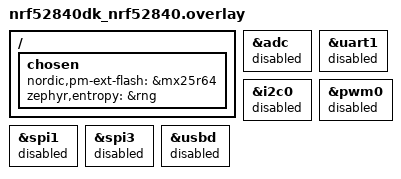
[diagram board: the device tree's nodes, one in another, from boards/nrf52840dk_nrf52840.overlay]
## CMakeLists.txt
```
#
# Copyright (c) 2021 Nordic Semiconductor ASA
#
# SPDX-License-Identifier: LicenseRef-Nordic-5-Clause
#

cmake_minimum_required(VERSION 3.20.0)

find_package(Zephyr HINTS $ENV{ZEPHYR_BASE})

project(matter-template)

# Enable GNU STD support and initialize the Matter Data Model.
include(${ZEPHYR_CONNECTEDHOMEIP_MODULE_DIR}/config/nrfconnect/app/enable-gnu-std.cmake)
include(${ZEPHYR_CONNECTEDHOMEIP_MODULE_DIR}/src/app/chip_data_model.cmake)

# NORDIC SDK APP START

# Include all source files that are located in the Matter common directory.
include(${ZEPHYR_NRF_MODULE_DIR}/samples/matter/common/cmake/source_common.cmake)

target_include_directories(app PRIVATE
    src
    ${CONFIG_NCS_SAMPLE_MATTER_ZAP_FILES_PATH}
)

target_sources(app PRIVATE
    src/app_task.cpp
    src/main.cpp
)

chip_configure_data_model(app
    INCLUDE_SERVER
    BYPASS_IDL
    GEN_DIR ${CONFIG_NCS_SAMPLE_MATTER_ZAP_FILES_PATH}/zap-generated
    ZAP_FILE ${CMAKE_CURRENT_SOURCE_DIR}/${CONFIG_NCS_SAMPLE_MATTER_ZAP_FILES_PATH}/template.zap
)
# NORDIC SDK APP END
```

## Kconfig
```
#
# Copyright (c) 2022 Nordic Semiconductor
#
# SPDX-License-Identifier: LicenseRef-Nordic-5-Clause
#
mainmenu "Matter nRF Connect Template Example Application"

# Sample configuration used for Thread networking
if NET_L2_OPENTHREAD

choice OPENTHREAD_NORDIC_LIBRARY_CONFIGURATION
	default OPENTHREAD_NORDIC_LIBRARY_MTD
endchoice

choice OPENTHREAD_DEVICE_TYPE
	default OPENTHREAD_MTD
endchoice

endif # NET_L2_OPENTHREAD

source "${ZEPHYR_CONNECTEDHOMEIP_MODULE_DIR}/config/nrfconnect/chip-module/Kconfig.features"
source "${ZEPHYR_CONNECTEDHOMEIP_MODULE_DIR}/config/nrfconnect/chip-module/Kconfig.defaults"
source "${ZEPHYR_NRF_MODULE_DIR}/samples/matter/common/src/Kconfig"
source "Kconfig.zephyr"
```

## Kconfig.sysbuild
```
#
# Copyright (c) 2023 Nordic Semiconductor ASA
#
# SPDX-License-Identifier: LicenseRef-Nordic-5-Clause
#

config WIFI_NRF70
	default y if BOARD_NRF7002DK

#### Radio core selection
config NRF_DEFAULT_IPC_RADIO
	default y

# Enable IEEE802.15.4 serialization to network core
# This config automatically pulls in the `overlay-802154.conf` in the ipc_radio image
config NETCORE_IPC_RADIO_IEEE802154
	default y if (SOC_SERIES_NRF53X || SOC_SERIES_NRF54HX) && !WIFI_NRF70

# Enable Bluetooth serialization to network core
# This config automatically pulls in the `overlay-bt_hci_ipc.conf` in the ipc_radio image
config NETCORE_IPC_RADIO_BT_HCI_IPC
	default y if (SOC_SERIES_NRF53X || SOC_SERIES_NRF54HX)

#### Bootloader
choice BOOTLOADER
	default BOOTLOADER_MCUBOOT if !BOARD_NRF21540DK && !SOC_SERIES_NRF54HX
endchoice

if BOOTLOADER_MCUBOOT

#### DFU multi-image support
config DFU_MULTI_IMAGE_PACKAGE_BUILD
	default y

config DFU_MULTI_IMAGE_PACKAGE_APP
	default y

config PM_EXTERNAL_FLASH_MCUBOOT_SECONDARY
	default y

#### DFU network core configuration
if SOC_SERIES_NRF53X

config MCUBOOT_UPDATEABLE_IMAGES
	default 2

choice MCUBOOT_MODE
	default MCUBOOT_MODE_OVERWRITE_ONLY
endchoice

choice BOOT_SIGNATURE_TYPE
	default BOOT_SIGNATURE_TYPE_RSA
endchoice

config SECURE_BOOT_NETCORE
	default y

config NETCORE_APP_UPDATE
	default y

config DFU_MULTI_IMAGE_PACKAGE_NET
	default y

endif # SOC_SERIES_NRF53X

if BOARD_NRF54L15DK

# Disable checking the external drivers for nRF54L15 DKs.
config PM_OVERRIDE_EXTERNAL_DRIVER_CHECK
	default y

# override the mcuboot pad size, because it is not set globally for NS build.
config PM_MCUBOOT_PAD
	default 0x800

endif # BOARD_NRF54L15DK

endif # BOOTLOADER_MCUBOOT

if SOC_SERIES_NRF54HX

config SUIT_ENVELOPE
	default y

config SUIT_BUILD_FLASH_COMPANION
	default y

config SUIT_MULTI_IMAGE_PACKAGE_BUILD
	default y if MATTER_OTA

endif # SOC_SERIES_NRF54HX

#### Enable generating factory data
config MATTER_FACTORY_DATA_GENERATE
	default y if !BOARD_NRF21540DK

source "${ZEPHYR_BASE}/share/sysbuild/Kconfig"
```

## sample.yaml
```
sample:
  description: Matter Template sample
  name: Matter Template
tests:
  sample.matter.template.debug:
    sysbuild: true
    build_only: true
    extra_args: CONFIG_NCS_SAMPLE_MATTER_OPERATIONAL_KEYS_MIGRATION_TO_ITS=y
    integration_platforms:
      - nrf52840dk/nrf52840
      - nrf5340dk/nrf5340/cpuapp
      - nrf7002dk/nrf5340/cpuapp
      - nrf54l15dk/nrf54l15/cpuapp
      - nrf54l15dk/nrf54l15/cpuapp/ns
      - nrf54l15dk/nrf54l10/cpuapp
    platform_allow: nrf52840dk/nrf52840 nrf5340dk/nrf5340/cpuapp nrf7002dk/nrf5340/cpuapp
      nrf54l15dk/nrf54l15/cpuapp nrf54l15dk/nrf54l15/cpuapp/ns nrf54l15dk/nrf54l10/cpuapp
    tags: sysbuild ci_samples_matter
  sample.matter.template.release:
    sysbuild: true
    build_only: true
    extra_args: FILE_SUFFIX=release
      CONFIG_NCS_SAMPLE_MATTER_OPERATIONAL_KEYS_MIGRATION_TO_ITS=y
    integration_platforms:
      - nrf52840dk/nrf52840
      - nrf5340dk/nrf5340/cpuapp
      - nrf7002dk/nrf5340/cpuapp
      - nrf54l15dk/nrf54l15/cpuapp
      - nrf54l15dk/nrf54l15/cpuapp/ns
      - nrf54l15dk/nrf54l10/cpuapp
    platform_allow: nrf52840dk/nrf52840 nrf5340dk/nrf5340/cpuapp nrf7002dk/nrf5340/cpuapp
      nrf54l15dk/nrf54l15/cpuapp nrf54l15dk/nrf54l15/cpuapp/ns nrf54l15dk/nrf54l10/cpuapp
    tags: sysbuild ci_samples_matter
  sample.matter.template.lto:
    sysbuild: true
    build_only: true
    extra_args: CONFIG_NCS_SAMPLE_MATTER_OPERATIONAL_KEYS_MIGRATION_TO_ITS=y
      CONFIG_LTO=y CONFIG_ISR_TABLES_LOCAL_DECLARATION=y
    integration_platforms:
      - nrf52840dk/nrf52840
      - nrf5340dk/nrf5340/cpuapp
      - nrf7002dk/nrf5340/cpuapp
      - nrf54l15dk/nrf54l15/cpuapp
      - nrf54l15dk/nrf54l10/cpuapp
    platform_allow: nrf52840dk/nrf52840 nrf5340dk/nrf5340/cpuapp nrf7002dk/nrf5340/cpuapp
      nrf54l15dk/nrf54l15/cpuapp nrf54l15dk/nrf54l10/cpuapp
    tags: sysbuild ci_samples_matter
  sample.matter.template.smp_dfu:
    sysbuild: true
    build_only: true
    extra_args: CONFIG_CHIP_DFU_OVER_BT_SMP=y
      CONFIG_NCS_SAMPLE_MATTER_OPERATIONAL_KEYS_MIGRATION_TO_ITS=y
    integration_platforms:
      - nrf52840dk/nrf52840
      - nrf5340dk/nrf5340/cpuapp
      - nrf7002dk/nrf5340/cpuapp
      - nrf54l15dk/nrf54l15/cpuapp
      - nrf54l15dk/nrf54l15/cpuapp/ns
      - nrf54l15dk/nrf54l10/cpuapp
    platform_allow: nrf52840dk/nrf52840 nrf5340dk/nrf5340/cpuapp nrf7002dk/nrf5340/cpuapp
      nrf54l15dk/nrf54l15/cpuapp nrf54l15dk/nrf54l15/cpuapp/ns nrf54l15dk/nrf54l10/cpuapp
    tags: sysbuild ci_samples_matter
  sample.matter.template.smp_dfu.nrf54h20:
    sysbuild: true
    build_only: true
    extra_args: CONFIG_CHIP_DFU_OVER_BT_SMP=y
    integration_platforms:
      - nrf54h20dk/nrf54h20/cpuapp
    platform_allow: nrf54h20dk/nrf54h20/cpuapp
    tags: sysbuild ci_samples_matter
  sample.matter.template.nrf54h20.nrf7002eb:
    sysbuild: true
    build_only: true
    extra_args:
      - SB_CONFIG_WIFI_NRF70=y
      - template_SHIELD=nrf7002eb_interposer_p1 nrf7002eb
      - CONFIG_CHIP_WIFI=y
      - CONFIG_CHIP_BOOTLOADER_NONE=y
      - CONFIG_CHIP_OTA_REQUESTOR=n
      - SB_CONFIG_MATTER_OTA=n
      - CONFIG_LTO=y
      - CONFIG_ISR_TABLES_LOCAL_DECLARATION=y
    integration_platforms:
      - nrf54h20dk/nrf54h20/cpuapp
    platform_allow: nrf54h20dk/nrf54h20/cpuapp
    tags: sysbuild ci_samples_matter
  sample.matter.template.release.internal.smp_dfu:
    sysbuild: true
    build_only: true
    extra_args: FILE_SUFFIX=internal CONFIG_CHIP_DFU_OVER_BT_SMP=y
      CONFIG_NCS_SAMPLE_MATTER_OPERATIONAL_KEYS_MIGRATION_TO_ITS=y
    integration_platforms:
      - nrf54l15dk/nrf54l15/cpuapp
    platform_allow: nrf54l15dk/nrf54l15/cpuapp
    tags: sysbuild ci_samples_matter
  sample.matter.template.cc3xx_backend:
    sysbuild: true
    build_only: true
    extra_args: CONFIG_PSA_CRYPTO_DRIVER_CC3XX=y
    integration_platforms:
      - nrf52840dk/nrf52840
      - nrf5340dk/nrf5340/cpuapp
    platform_allow: nrf52840dk/nrf52840 nrf5340dk/nrf5340/cpuapp
    tags: sysbuild ci_samples_matter
```

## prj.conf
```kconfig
#
# Copyright (c) 2021 Nordic Semiconductor ASA
#
# SPDX-License-Identifier: LicenseRef-Nordic-5-Clause
#

# This sample uses Kconfig.defaults to set options common for all
# samples. This file should contain only options specific for this sample
# or overrides of default values.

# Enable CHIP
CONFIG_CHIP=y
CONFIG_CHIP_PROJECT_CONFIG="src/chip_project_config.h"
# 32768 == 0x8000 (example Product ID added temporaly,
# but it must be changed with proper PID from the list:
# https://github.com/project-chip/connectedhomeip/blob/482e6fd03196a6de45465a90003947ef4b86e0b1/docs/examples/discussion/PID_allocation_for_example_apps.md)
CONFIG_CHIP_DEVICE_PRODUCT_ID=32768
CONFIG_STD_CPP17=y

# Enable Matter pairing automatically on application start.
CONFIG_CHIP_ENABLE_PAIRING_AUTOSTART=y

# Enable Matter extended announcement and increase duration to 1 hour.
CONFIG_CHIP_BLE_EXT_ADVERTISING=y
CONFIG_CHIP_BLE_ADVERTISING_DURATION=60

# Add support for LEDs and buttons on Nordic development kits
CONFIG_DK_LIBRARY=y

# Bluetooth Low Energy configuration
CONFIG_BT_DEVICE_NAME="MatterTemplate"

# Other settings
CONFIG_THREAD_NAME=y
CONFIG_MPU_STACK_GUARD=y
CONFIG_RESET_ON_FATAL_ERROR=n
CONFIG_CHIP_LIB_SHELL=y
CONFIG_NCS_SAMPLE_MATTER_TEST_SHELL=y

# Disable NFC commissioning
CONFIG_CHIP_NFC_COMMISSIONING=n

# Reduce application size
CONFIG_USE_SEGGER_RTT=n

# Enable Factory Data feature
CONFIG_CHIP_FACTORY_DATA=y
CONFIG_CHIP_FACTORY_DATA_BUILD=y
```

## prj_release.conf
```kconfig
#
# Copyright (c) 2021 Nordic Semiconductor ASA
#
# SPDX-License-Identifier: LicenseRef-Nordic-5-Clause
#

# This sample uses Kconfig.defaults to set options common for all
# samples. This file should contain only options specific for this sample
# or overrides of default values.

# Enable CHIP
CONFIG_CHIP=y
CONFIG_CHIP_PROJECT_CONFIG="src/chip_project_config.h"
# 32768 == 0x8000 (example Product ID added temporaly,
# but it must be changed with proper PID from the list:
# https://github.com/project-chip/connectedhomeip/blob/482e6fd03196a6de45465a90003947ef4b86e0b1/docs/examples/discussion/PID_allocation_for_example_apps.md)
CONFIG_CHIP_DEVICE_PRODUCT_ID=32768
CONFIG_STD_CPP17=y

# Enable Matter pairing automatically on application start.
CONFIG_CHIP_ENABLE_PAIRING_AUTOSTART=y

# Enable Matter extended announcement and increase duration to 1 hour.
CONFIG_CHIP_BLE_EXT_ADVERTISING=y
CONFIG_CHIP_BLE_ADVERTISING_DURATION=60

# Add support for LEDs and buttons on Nordic development kits
CONFIG_DK_LIBRARY=y

# Bluetooth Low Energy configuration
CONFIG_BT_DEVICE_NAME="MatterTemplate"

# Enable system reset on fatal error
CONFIG_RESET_ON_FATAL_ERROR=y

# Disable all debug features
CONFIG_USE_SEGGER_RTT=n
CONFIG_SHELL=n
CONFIG_OPENTHREAD_SHELL=n
CONFIG_CONSOLE=n
CONFIG_UART_CONSOLE=n
CONFIG_SERIAL=n
CONFIG_LOG=n
CONFIG_LOG_MODE_MINIMAL=n
CONFIG_ASSERT_VERBOSE=n
CONFIG_ASSERT_NO_FILE_INFO=y
CONFIG_PRINTK=n
CONFIG_PRINTK_SYNC=n
CONFIG_THREAD_NAME=n
CONFIG_BOOT_BANNER=n

# Disable NFC commissioning
CONFIG_CHIP_NFC_COMMISSIONING=n

# Enable Factory Data feature
CONFIG_CHIP_FACTORY_DATA=y
CONFIG_CHIP_FACTORY_DATA_BUILD=y

# Enable Watchdog
CONFIG_NCS_SAMPLE_MATTER_WATCHDOG=y
```

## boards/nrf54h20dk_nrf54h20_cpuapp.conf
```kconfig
#
# Copyright (c) 2024 Nordic Semiconductor ASA
#
# SPDX-License-Identifier: LicenseRef-Nordic-5-Clause
#

# Disable Oberon PSA crypto drivers
CONFIG_PSA_CRYPTO_DRIVER_OBERON=n

# Enable PSA crypto from SSF client
CONFIG_PSA_SSF_CRYPTO_CLIENT=y
CONFIG_SSF_PSA_CRYPTO_SERVICE_ENABLED=y

# Disable Data Cache
CONFIG_DCACHE=n

# Set the ZMS sector count to match the settings partition size that is 32 kB for this application.
CONFIG_SETTINGS_ZMS_SECTOR_COUNT=8
# Workaround required as Zephyr L2 implies usage of NVS backend for settings.
# It should be removed once the proper fix will be applied in Zephyr.
CONFIG_NVS=n

# Enable cache processing for application core.
# It will add the application firmware to the cache partition.
CONFIG_SUIT_DFU_CACHE_EXTRACT_IMAGE=y

# TODO: Enable factory data and DAC key migration once it is available
CONFIG_CHIP_FACTORY_DATA=n
CONFIG_CHIP_CRYPTO_PSA_MIGRATE_DAC_PRIV_KEY=n

# TODO: Workaround to be removed once Zephyr's CONFIG_FPROTECT is supported on nRF54H20.
CONFIG_CHIP_FACTORY_DATA_WRITE_PROTECT=n

# Disable GPD
CONFIG_SOC_NRF54H20_GPD=n
```

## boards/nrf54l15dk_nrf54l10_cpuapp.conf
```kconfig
#
# Copyright (c) 2024 Nordic Semiconductor ASA
#
# SPDX-License-Identifier: LicenseRef-Nordic-5-Clause
#

# Multirole is the only currently supported role by SoftDevice.
CONFIG_BT_LL_SOFTDEVICE_MULTIROLE=y

# nRF54L15 requires bigger stack sizes than nRF52/nRF53 families
CONFIG_CHIP_MALLOC_SYS_HEAP_SIZE=10240
CONFIG_MPSL_WORK_STACK_SIZE=2048

# Set the ZMS sector count to match the settings partition size that is 40 kB for this application.
CONFIG_SETTINGS_ZMS_SECTOR_COUNT=10

# Workaround required as Zephyr L2 implies usage of NVS backend for settings.
# It should be removed once the proper fix will be applied in Zephyr.
CONFIG_NVS=n

# Disabling of unused RAM blocks to reduce power consumption is not yet available for nRF54L10 SoC
CONFIG_RAM_POWER_DOWN_LIBRARY=n
```

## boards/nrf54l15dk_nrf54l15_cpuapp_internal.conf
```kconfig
#
# Copyright (c) 2024 Nordic Semiconductor ASA
#
# SPDX-License-Identifier: LicenseRef-Nordic-5-Clause
#

# Multirole is the only currently supported role by SoftDevice.
CONFIG_BT_LL_SOFTDEVICE_MULTIROLE=y

# nRF54L15 requires bigger stack sizes than nRF52/nRF53 families
CONFIG_CHIP_MALLOC_SYS_HEAP_SIZE=10240
CONFIG_MPSL_WORK_STACK_SIZE=2048

# Set the ZMS sector count to match the settings partition size that is 40 kB for this application.
CONFIG_SETTINGS_ZMS_SECTOR_COUNT=10
# Workaround required as Zephyr L2 implies usage of NVS backend for settings.
# It should be removed once the proper fix will be applied in Zephyr.
CONFIG_NVS=n

# Disable SPI
CONFIG_CHIP_SPI_NOR=n

# Enable Watchdog
CONFIG_NCS_SAMPLE_MATTER_WATCHDOG=y

# Enable LTO
CONFIG_LTO=y
CONFIG_ISR_TABLES_LOCAL_DECLARATION=y
```

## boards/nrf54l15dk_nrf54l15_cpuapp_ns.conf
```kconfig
#
# Copyright (c) 2024 Nordic Semiconductor ASA
#
# SPDX-License-Identifier: LicenseRef-Nordic-5-Clause
#

# Multirole is the only currently supported role by SoftDevice.
CONFIG_BT_LL_SOFTDEVICE_MULTIROLE=y

# TODO: Workaround to be removed once Zephyr's CONFIG_FPROTECT is supported on nRF54L_ns
CONFIG_CHIP_FACTORY_DATA_WRITE_PROTECT=n

# nRF54L15 requires bigger stack sizes than nRF52/nRF53 families
CONFIG_CHIP_MALLOC_SYS_HEAP_SIZE=10240
CONFIG_MPSL_WORK_STACK_SIZE=2048

# Set the ZMS sector count to match the settings partition size that is 40 kB for this application.
CONFIG_SETTINGS_ZMS_SECTOR_COUNT=10
# Workaround required as Zephyr L2 implies usage of NVS backend for settings.
# It should be removed once the proper fix will be applied in Zephyr.
CONFIG_NVS=n
```

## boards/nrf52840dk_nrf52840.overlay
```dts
/* Copyright (c) 2021 Nordic Semiconductor ASA
 *
 * SPDX-License-Identifier: LicenseRef-Nordic-5-Clause
 */

/ {
	chosen {
		nordic,pm-ext-flash = &mx25r64;
	};
};


/ {
	/*
	* In some default configurations within the nRF Connect SDK,
	* e.g. on nRF52840, the chosen zephyr,entropy node is &cryptocell.
	* This devicetree overlay ensures that default is overridden wherever it
	* is set, as this application uses the RNG node for entropy exclusively.
	*/
	chosen {
		zephyr,entropy = &rng;
	};
};

/* Disable unused peripherals to reduce power consumption */
&adc {
	status = "disabled";
};
&uart1 {
	status = "disabled";
};
&i2c0 {
	status = "disabled";
};
&pwm0 {
	status = "disabled";
};
&spi1 {
	status = "disabled";
};
&spi3 {
	status = "disabled";
};
&usbd {
	status = "disabled";
};
```

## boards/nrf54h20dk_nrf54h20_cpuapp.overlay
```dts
/*
 * Copyright (c) 2024 Nordic Semiconductor ASA
 *
 * SPDX-License-Identifier: LicenseRef-Nordic-5-Clause
 */

// Base path of the following includes points to the nrf/include directory.
#include <../samples/matter/common/dts/nrf54h20/nrf54h20_cpuapp_peripherals.dtsi>
#include <../samples/matter/common/dts/nrf54h20/nrf54h20_cpuapp_memory_map.dtsi>
#include <../samples/matter/common/dts/nrf54h20/nrf54h20_ram_allocation.dtsi>
```

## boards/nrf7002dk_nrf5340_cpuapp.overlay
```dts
/*
 * Copyright (c) 2021 Nordic Semiconductor ASA
 *
 * SPDX-License-Identifier: LicenseRef-Nordic-5-Clause
 */

#include <zephyr/dt-bindings/ipc_service/static_vrings.h>

/ {
	chosen {
		nordic,pm-ext-flash = &mx25r64;
	};

	aliases {
		watchdog0 = &wdt0;
	};

};

/* Set IPC thread priority to the highest value to not collide with other threads. */
&ipc0 {
    zephyr,priority = <0 PRIO_COOP>;
};
```

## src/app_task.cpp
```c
/*
 * Copyright (c) 2021 Nordic Semiconductor ASA
 *
 * SPDX-License-Identifier: LicenseRef-Nordic-5-Clause
 */

#include "app_task.h"

#include "app/matter_init.h"
#include "app/task_executor.h"
#include "board/board.h"
#include "lib/core/CHIPError.h"
#include "lib/support/CodeUtils.h"

#ifdef CONFIG_CHIP_OTA_REQUESTOR
#include "dfu/ota/ota_util.h"
#endif

#include <app/server/OnboardingCodesUtil.h>

#include <zephyr/logging/log.h>

LOG_MODULE_DECLARE(app, CONFIG_CHIP_APP_LOG_LEVEL);

using namespace ::chip;
using namespace ::chip::app;
using namespace ::chip::DeviceLayer;

CHIP_ERROR AppTask::Init()
{
	/* Initialize Matter stack */
	ReturnErrorOnFailure(Nrf::Matter::PrepareServer());

	if (!Nrf::GetBoard().Init()) {
		LOG_ERR("User interface initialization failed.");
		return CHIP_ERROR_INCORRECT_STATE;
	}

	/* Register Matter event handler that controls the connectivity status LED based on the captured Matter network
	 * state. */
	ReturnErrorOnFailure(Nrf::Matter::RegisterEventHandler(Nrf::Board::DefaultMatterEventHandler, 0));

	return Nrf::Matter::StartServer();
}

CHIP_ERROR AppTask::StartApp()
{
	ReturnErrorOnFailure(Init());

	while (true) {
		Nrf::DispatchNextTask();
	}

	return CHIP_NO_ERROR;
}
```
